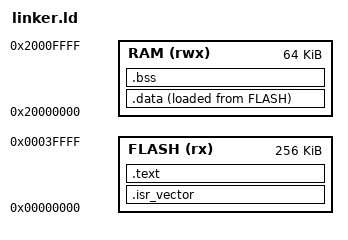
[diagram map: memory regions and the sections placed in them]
ENTRY(Reset_Handler)

_estack = ORIGIN(RAM) + LENGTH(RAM);

MEMORY
{
  FLASH (rx)  : ORIGIN = 0x00000000, LENGTH = 256K
  RAM   (rwx) : ORIGIN = 0x20000000, LENGTH = 64K
}

SECTIONS
{
  .isr_vector :
  {
    . = ALIGN(4);
    KEEP(*(.isr_vector))
    . = ALIGN(4);
  } > FLASH

  .text :
  {
    . = ALIGN(4);
    *(.text)
    *(.text*)
    *(.rodata)
    *(.rodata*)
    . = ALIGN(4);
  } > FLASH

  .data :
  {
    . = ALIGN(4);
    *(.data)
    *(.data*)
    . = ALIGN(4);
  } > RAM AT > FLASH

  .bss :
  {
    . = ALIGN(4);
    *(.bss)
    *(.bss*)
    . = ALIGN(4);
  } > RAM
}
